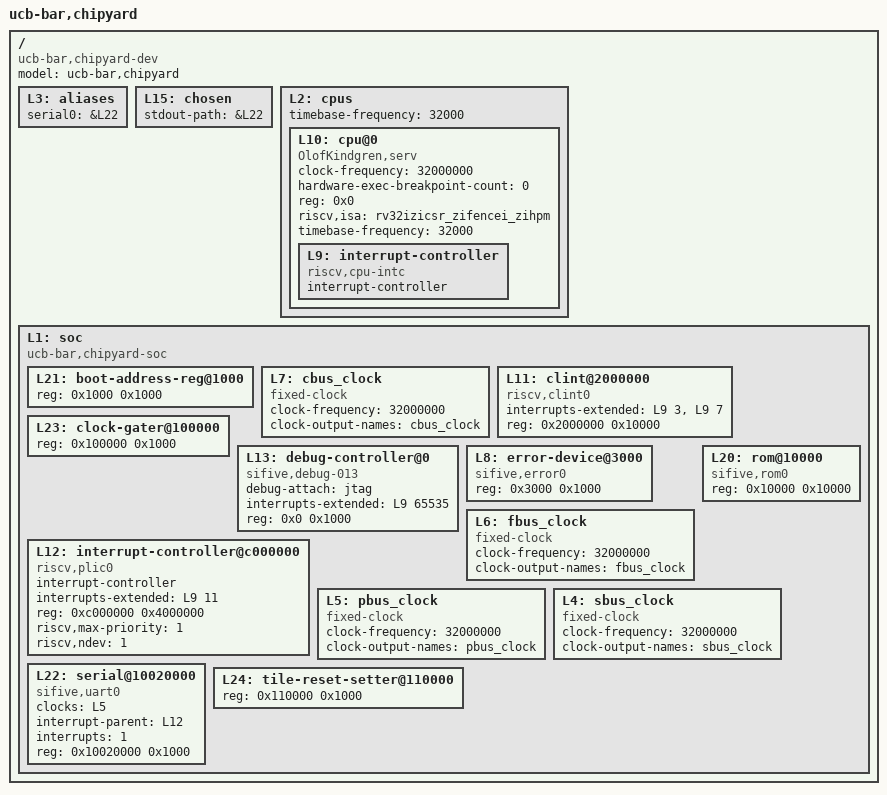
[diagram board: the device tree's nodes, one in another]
/dts-v1/;

/ {
	#address-cells = <1>;
	#size-cells = <1>;
	compatible = "ucb-bar,chipyard-dev";
	model = "ucb-bar,chipyard";
	L3: aliases {
		serial0 = &L22;
	};
	L15: chosen {
		stdout-path = &L22;
	};
	L2: cpus {
		#address-cells = <1>;
		#size-cells = <0>;
		timebase-frequency = <32000>;
		L10: cpu@0 {
			clock-frequency = <32000000>;
			compatible = "OlofKindgren,serv", "riscv";
			device_type = "cpu";
			hardware-exec-breakpoint-count = <0>;
			reg = <0x0>;
			riscv,isa = "rv32izicsr_zifencei_zihpm";
			status = "okay";
			timebase-frequency = <32000>;
			L9: interrupt-controller {
				#interrupt-cells = <1>;
				compatible = "riscv,cpu-intc";
				interrupt-controller;
			};
		};
	};
	L1: soc {
		#address-cells = <1>;
		#size-cells = <1>;
		compatible = "ucb-bar,chipyard-soc", "simple-bus";
		ranges;
		L21: boot-address-reg@1000 {
			reg = <0x1000 0x1000>;
			reg-names = "control";
		};
		L7: cbus_clock {
			#clock-cells = <0>;
			clock-frequency = <32000000>;
			clock-output-names = "cbus_clock";
			compatible = "fixed-clock";
		};
		L11: clint@2000000 {
			compatible = "riscv,clint0";
			interrupts-extended = <&L9 3 &L9 7>;
			reg = <0x2000000 0x10000>;
			reg-names = "control";
		};
		L23: clock-gater@100000 {
			reg = <0x100000 0x1000>;
			reg-names = "control";
		};
		L13: debug-controller@0 {
			compatible = "sifive,debug-013", "riscv,debug-013";
			debug-attach = "jtag";
			interrupts-extended = <&L9 65535>;
			reg = <0x0 0x1000>;
			reg-names = "control";
		};
		L8: error-device@3000 {
			compatible = "sifive,error0";
			reg = <0x3000 0x1000>;
		};
		L6: fbus_clock {
			#clock-cells = <0>;
			clock-frequency = <32000000>;
			clock-output-names = "fbus_clock";
			compatible = "fixed-clock";
		};
		L12: interrupt-controller@c000000 {
			#interrupt-cells = <1>;
			compatible = "riscv,plic0";
			interrupt-controller;
			interrupts-extended = <&L9 11>;
			reg = <0xc000000 0x4000000>;
			reg-names = "control";
			riscv,max-priority = <1>;
			riscv,ndev = <1>;
		};
		L5: pbus_clock {
			#clock-cells = <0>;
			clock-frequency = <32000000>;
			clock-output-names = "pbus_clock";
			compatible = "fixed-clock";
		};
		L20: rom@10000 {
			compatible = "sifive,rom0";
			reg = <0x10000 0x10000>;
			reg-names = "mem";
		};
		L4: sbus_clock {
			#clock-cells = <0>;
			clock-frequency = <32000000>;
			clock-output-names = "sbus_clock";
			compatible = "fixed-clock";
		};
		L22: serial@10020000 {
			clocks = <&L5>;
			compatible = "sifive,uart0";
			interrupt-parent = <&L12>;
			interrupts = <1>;
			reg = <0x10020000 0x1000>;
			reg-names = "control";
		};
		L24: tile-reset-setter@110000 {
			reg = <0x110000 0x1000>;
			reg-names = "control";
		};
	};
};
